# STM32F411 register map
File version: 1.9
CPU: CM4 r0p1, little endian, MPU, FPU, 4 interrupt priority bits
Registers are 32-bit, read-write, reset 0x0 unless marked. A register's access mark holds for its fields unless they carry their own. Offsets are from the block's base; [hi:lo] are bit positions; lines under a group give offsets from that group; {n}, {i} and the like mark numbered series; <NAME> marks a mode.

## OTG_FS_HOST — USB on the go full speed
Base 0x50000400
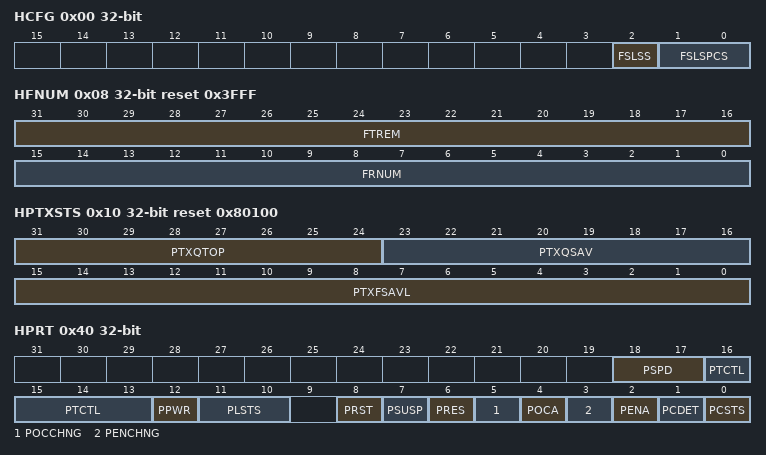
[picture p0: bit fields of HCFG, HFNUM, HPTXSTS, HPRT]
0x00 HCFG — OTG_FS host configuration register (OTG_FS_HCFG)
  [2] FSLSS — FS- and LS-only support
  [1:0] FSLSPCS — FS/LS PHY clock select
0x04 HFIR reset 0xEA60 — OTG_FS Host frame interval register
  [15:0] FRIVL — Frame interval
0x08 HFNUM ro reset 0x3FFF — OTG_FS host frame number/frame time remaining register (OTG_FS_HFNUM)
  [31:16] FTREM — Frame time remaining
  [15:0] FRNUM — Frame number
0x10 HPTXSTS access per field reset 0x80100 — OTG_FS_Host periodic transmit FIFO/queue status register (OTG_FS_HPTXSTS)
  [31:24] PTXQTOP ro — Top of the periodic transmit request queue
  [23:16] PTXQSAV ro — Periodic transmit request queue space available
  [15:0] PTXFSAVL rw — Periodic transmit data FIFO space available
0x14 HAINT ro — OTG_FS Host all channels interrupt register
  [15:0] HAINT — Channel interrupts
0x18 HAINTMSK — OTG_FS host all channels interrupt mask register
  [15:0] HAINTM — Channel interrupt mask
0x40 HPRT access per field — OTG_FS host port control and status register (OTG_FS_HPRT)
  [18:17] PSPD ro — Port speed
  [16:13] PTCTL rw — Port test control
  [12] PPWR rw — Port power
  [11:10] PLSTS ro — Port line status
  [8] PRST rw — Port reset
  [7] PSUSP rw — Port suspend
  [6] PRES rw — Port resume
  [5] POCCHNG rw — Port overcurrent change
  [4] POCA ro — Port overcurrent active
  [3] PENCHNG rw — Port enable/disable change
  [2] PENA rw — Port enable
  [1] PCDET rw — Port connect detected
  [0] PCSTS ro — Port connect status
{0x100+0x20*i} HC{i} (i=0..7) group — Host channel
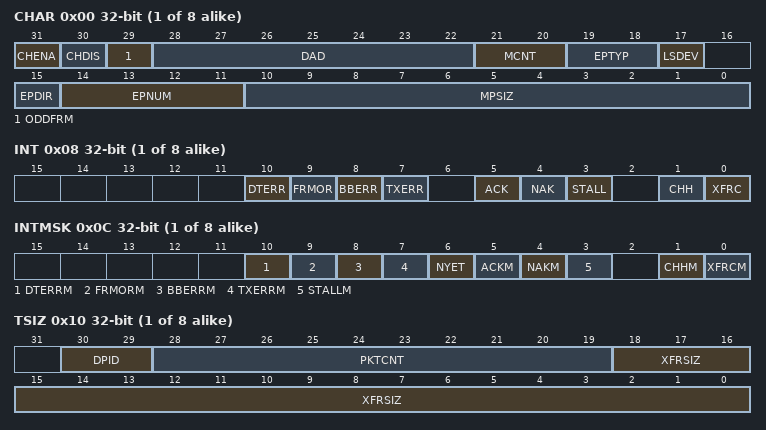
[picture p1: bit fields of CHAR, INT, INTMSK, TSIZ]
  0x00 CHAR — OTG_FS host channel-0 characteristics register (OTG_FS_HCCHAR0)
    [31] CHENA — Channel enable
    [30] CHDIS — Channel disable
    [29] ODDFRM — Odd frame
    [28:22] DAD — Device address
    [21:20] MCNT — Multicount
    [19:18] EPTYP — Endpoint type
    [17] LSDEV — Low-speed device
    [15] EPDIR — Endpoint direction
    [14:11] EPNUM — Endpoint number
    [10:0] MPSIZ — Maximum packet size
  0x08 INT — OTG_FS host channel-0 interrupt register (OTG_FS_HCINT0)
    [10] DTERR — Data toggle error
    [9] FRMOR — Frame overrun
    [8] BBERR — Babble error
    [7] TXERR — Transaction error
    [5] ACK — ACK response received/transmitted interrupt
    [4] NAK — NAK response received interrupt
    [3] STALL — STALL response received interrupt
    [1] CHH — Channel halted
    [0] XFRC — Transfer completed
  0x0C INTMSK — OTG_FS host channel-0 mask register (OTG_FS_HCINTMSK0)
    [10] DTERRM — Data toggle error mask
    [9] FRMORM — Frame overrun mask
    [8] BBERRM — Babble error mask
    [7] TXERRM — Transaction error mask
    [6] NYET — response received interrupt mask
    [5] ACKM — ACK response received/transmitted interrupt mask
    [4] NAKM — NAK response received interrupt mask
    [3] STALLM — STALL response received interrupt mask
    [1] CHHM — Channel halted mask
    [0] XFRCM — Transfer completed mask
  0x10 TSIZ — OTG_FS host channel-0 transfer size register
    [30:29] DPID — Data PID
    [28:19] PKTCNT — Packet count
    [18:0] XFRSIZ — Transfer size

## OTG_FS_PWRCLK — USB on the go full speed
Base 0x50000E00
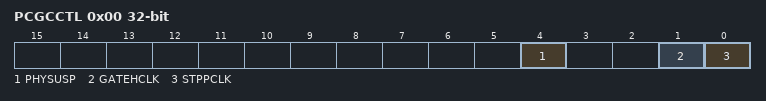
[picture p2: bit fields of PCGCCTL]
0x00 PCGCCTL — OTG_FS power and clock gating control register
  [4] PHYSUSP — PHY Suspended
  [1] GATEHCLK
  [0] STPPCLK — Stop PHY clock

## PWR — Power control
Base 0x40007000
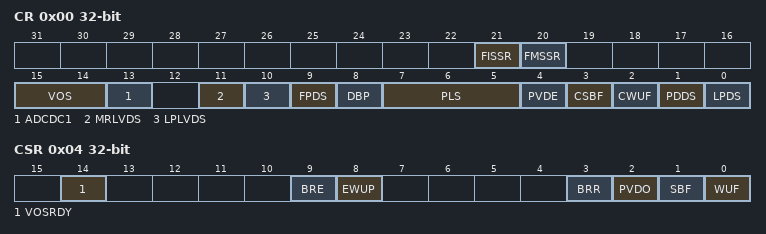
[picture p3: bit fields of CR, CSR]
0x00 CR — power control register
  [21] FISSR — Flash Interface Stop while System Run
    0=Run (Flash Interface clock run (Default value)); 1=Off (Flash Interface clock off)
  [20] FMSSR — Flash Memory Sleep System Run
    0=Standard (Flash standard mode (Default value)); 1=Forced (Flash forced to be in STOP or DeepPower Down mode (depending of FPDS value bit) by hardware)
  [15:14] VOS — Regulator voltage scaling output selection
    1=Scale 3 mode <= 64 MHz; 2=Scale 2 mode (reset value) <= 84 MHz; 3=Scale 1 mode <= 100 MHz
  [13] ADCDC1
  [11] MRLVDS — Main regulator Low Voltage in Deep Sleep
    0=Scale3 (Main regulator in Voltage scale 3 when the device is in Stop mode); 1=LowVoltage (Main regulator in Low Voltage and Flash memory in Deep Sleep mode when the device is in Stop mode)
  [10] LPLVDS — Low-power regulator Low Voltage in Deep Sleep
    0=On (Low-power regulator on if LPDS bit is set when the device is in Stop mode); 1=UnderDrive (Low-power regulator in Low Voltage and Flash memory in Deep Sleep mode if LPDS bit is set when device is in Stop mode)
  [9] FPDS — Flash power down in Stop mode
    0=Idle (Flash memory not in power-down when the device is in Stop mode); 1=PowerDown (Flash memory in power-down when the device is in Stop mode)
  [8] DBP — Disable backup domain write protection
    0=Protected (Access to RTC and RTC Backup registers and backup SRAM disabled); 1=Writable (Access to RTC and RTC Backup registers and backup SRAM enabled)
  [7:5] PLS — PVD level selection
  [4] PVDE — Power voltage detector enable
    0=Disabled (PVD disabled); 1=Enabled (PVD enabled)
  [3] CSBF — Clear standby flag
    on read: 0=Zero (This bit is always read as 0) | on write: 1=Clear the SBF Standby Flag
  [2] CWUF — Clear wakeup flag
    on read: 0=Zero (This bit is always read as 0) | on write: 1=Clear the WUPF Wakeup Flag **after 2 System clock cycles**
  [1] PDDS — Power down deepsleep
    0=Enter Stop mode when the CPU enters deepsleep. The regulator status depends on the LPDS bit; 1=Enter Standby mode when the CPU enters deepsleep
  [0] LPDS — Low-power deep sleep
    0=Main voltage regulator ON during Stop mode; 1=Low-power voltage regulator ON during Stop mode
0x04 CSR access per field — power control/status register
  [14] VOSRDY ro — Regulator voltage scaling output selection ready bit
    0=NotReady; 1=Ready
  [9] BRE rw — Backup regulator enable
    0=Disabled (Backup regulator disabled); 1=Enabled (Backup regulator enabled)
  [8] EWUP rw — Enable WKUP pin
    0=GPIO (WKUP1 pin is used for general purpose I/O. An event on the WKUP1 pin does not wakeup the device from Standby mode); 1=WakeUp (WKUP1 pin is used for wakeup from Standby mode and forced in input pull down configuration (rising edge or falling on WKUP pin wakes-up the system from Standby mode))
  [3] BRR ro — Backup regulator ready
    0=NotReady (Backup Regulator not ready); 1=Ready (Backup Regulator ready)
  [2] PVDO ro — PVD output
    0=Higher (Vdd is higher than the PVD threshold selected with the PLS[2:0] bits); 1=Lower (Vdd is lower than the PVD threshold selected with the PLS[2:0] bits)
  [1] SBF ro — Standby flag
    0=InStandby (Device has not been in Standby mode); 1=NotInStandby (Device has been in Standby mode)
  [0] WUF ro — Wakeup flag
    0=NotOccurred (No wakeup event occurred); 1=Occurred (A wakeup event was received from the WKUP pin or from the RTC alarm (Alarm A or Alarm B), RTC Tamper event, RTC TimeStamp event or RTC Wakeup))
